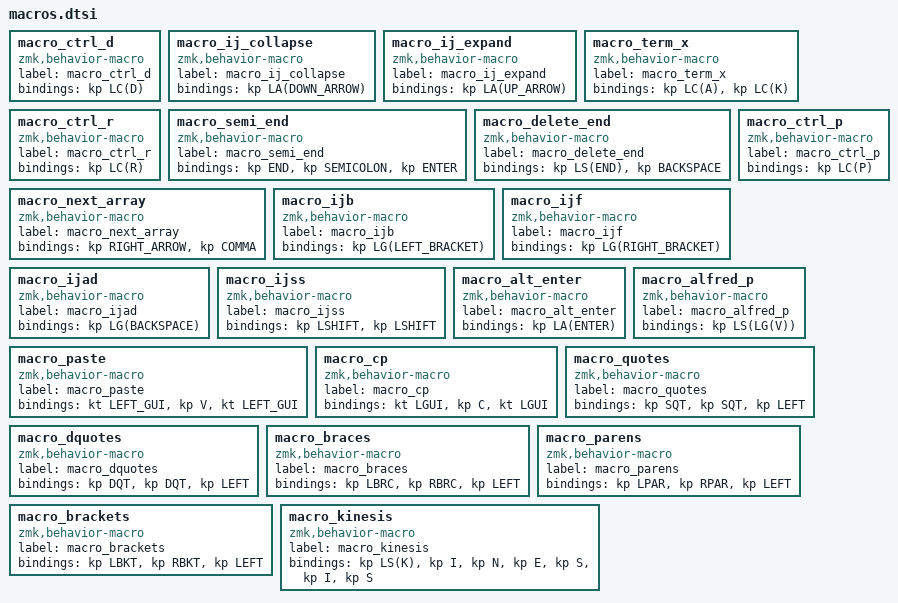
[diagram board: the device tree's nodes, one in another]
macro_ctrl_d: macro_ctrl_d{
compatible = "zmk,behavior-macro";
label = "macro_ctrl_d";
#binding-cells = <0>;
bindings = <&kp LC(D)>;
};
macro_ij_collapse: macro_ij_collapse{
compatible = "zmk,behavior-macro";
label = "macro_ij_collapse";
#binding-cells = <0>;
bindings = <&kp LA(DOWN_ARROW)>;
};
macro_ij_expand: macro_ij_expand{
compatible = "zmk,behavior-macro";
label = "macro_ij_expand";
#binding-cells = <0>;
bindings = <&kp LA(UP_ARROW)>;
};
macro_term_x: macro_term_x{
compatible = "zmk,behavior-macro";
label = "macro_term_x";
#binding-cells = <0>;
bindings = <&kp LC(A)>, <&kp LC(K)>;
};
macro_ctrl_r: macro_ctrl_r{
compatible = "zmk,behavior-macro";
label = "macro_ctrl_r";
#binding-cells = <0>;
bindings = <&kp LC(R)>;
};
macro_semi_end: macro_semi_end{
compatible = "zmk,behavior-macro";
label = "macro_semi_end";
#binding-cells = <0>;
bindings = <&kp END>, <&kp SEMICOLON>, <&kp ENTER>;
};
macro_delete_end: macro_delete_end{
compatible = "zmk,behavior-macro";
label = "macro_delete_end";
#binding-cells = <0>;
bindings = <&kp LS(END)>, <&kp BACKSPACE>;
};
macro_next_array: macro_next_array{
compatible = "zmk,behavior-macro";
label = "macro_next_array";
#binding-cells = <0>;
bindings = <&kp RIGHT_ARROW>, <&kp COMMA>;
};
macro_ijb: macro_ijb{
compatible = "zmk,behavior-macro";
label = "macro_ijb";
#binding-cells = <0>;
bindings = <&kp LG(LEFT_BRACKET)>;
};
macro_ijf: macro_ijf{
compatible = "zmk,behavior-macro";
label = "macro_ijf";
#binding-cells = <0>;
bindings = <&kp LG(RIGHT_BRACKET)>;
};
macro_ijad: macro_ijad{
compatible = "zmk,behavior-macro";
label = "macro_ijad";
#binding-cells = <0>;
bindings = <&kp LG(BACKSPACE)>;
};
macro_ijss: macro_ijss{
compatible = "zmk,behavior-macro";
label = "macro_ijss";
#binding-cells = <0>;
bindings = <&kp LSHIFT>, <&kp LSHIFT>;
};
macro_ctrl_p: macro_ctrl_p{
compatible = "zmk,behavior-macro";
label = "macro_ctrl_p";
#binding-cells = <0>;
bindings = <&kp LC(P)>;
};
macro_alt_enter: macro_alt_enter{
compatible = "zmk,behavior-macro";
label = "macro_alt_enter";
#binding-cells = <0>;
bindings = <&kp LA(ENTER)>;
};
macro_alfred_p: macro_alfred_p{
compatible = "zmk,behavior-macro";
label = "macro_alfred_p";
#binding-cells = <0>;
bindings = <&kp LS(LG(V))>;
};
macro_paste: macro_paste{
compatible = "zmk,behavior-macro";
label = "macro_paste";
#binding-cells = <0>;
bindings = <&kt LEFT_GUI>, <&kp V>, <&kt LEFT_GUI>;
};
macro_cp: macro_cp{
compatible = "zmk,behavior-macro";
label = "macro_cp";
#binding-cells = <0>;
bindings = <&kt LGUI>, <&kp C>, <&kt LGUI>;
};
macro_quotes: macro_quotes{
compatible = "zmk,behavior-macro";
label = "macro_quotes";
#binding-cells = <0>;
bindings = <&kp SQT>, <&kp SQT>, <&kp LEFT>;
};
macro_dquotes: macro_dquotes{
compatible = "zmk,behavior-macro";
label = "macro_dquotes";
#binding-cells = <0>;
bindings = <&kp DQT>, <&kp DQT>, <&kp LEFT>;
};
macro_braces: macro_braces{
compatible = "zmk,behavior-macro";
label = "macro_braces";
#binding-cells = <0>;
bindings = <&kp LBRC>, <&kp RBRC>, <&kp LEFT>;
};
macro_parens: macro_parens{
compatible = "zmk,behavior-macro";
label = "macro_parens";
#binding-cells = <0>;
bindings = <&kp LPAR>, <&kp RPAR>, <&kp LEFT>;
};
macro_brackets: macro_brackets{
compatible = "zmk,behavior-macro";
label = "macro_brackets";
#binding-cells = <0>;
bindings = <&kp LBKT>, <&kp RBKT>, <&kp LEFT>;
};
macro_kinesis: macro_kinesis{
compatible = "zmk,behavior-macro";
label = "macro_kinesis";
#binding-cells = <0>;
bindings = <&kp LS(K)>, <&kp I>, <&kp N>, <&kp E>, <&kp S>, <&kp I>, <&kp S>;
};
